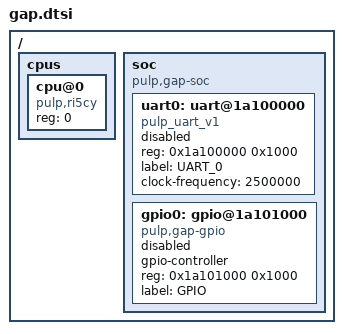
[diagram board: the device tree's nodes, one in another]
/*
 * Copyright (c) 2018 ETH Zurich, University of Bologna, GreenWaves Technologies
 *
 * SPDX-License-Identifier: Apache-2.0
 */

#include <dt-bindings/gpio/gpio.h>

/ {
	#address-cells = <1>;
	#size-cells = <1>;

	cpus {
		#address-cells = <1>;
		#size-cells = <0>;
		cpu@0 {
			compatible = "pulp,ri5cy", "riscv";
			reg = <0>;
		};
	};

	soc {
		#address-cells = <1>;
		#size-cells = <1>;
		compatible = "pulp,gap-soc", "simple-bus";
		ranges;

		uart0: uart@1a100000 {
			compatible = "pulp_uart_v1";
			reg = <0x1a100000 0x1000>;
			label = "UART_0";
			clock-frequency = <2500000>;

			status = "disabled";
		};

		gpio0: gpio@1a101000 {
			compatible = "pulp,gap-gpio";
			gpio-controller;
			reg = <0x1a101000 0x1000>;
			label = "GPIO";
			status = "disabled";
			#gpio-cells = <2>;
		};
	};
};
